VERSION "K24_6MT"

NS_ :

BS_:

BU_: METER PCM UNKNOWN

BO_ 422 SCM_0x1A6: 8 METER
 SG_ HEADLIGHT_STATE : 0|2@1+ (1,0) [0|3] ""  PCM
 SG_ LIGHTING_STATUS_TBD : 2|1@1+ (1,0) [0|1] ""  PCM
 SG_ STATUS_BIT_1 : 3|1@1+ (1,0) [0|1] ""  PCM
 SG_ PARKBRAKE_CURRENT_RAW : 4|1@1+ (1,0) [0|1] ""  PCM
 SG_ CRUISE_CONTROL_SYSTEM_SWITCH_STATUS : 5|3@1+ (1,0) [0|7] ""  PCM
 SG_ UNKNOWN_1 : 8|4@1+ (1,0) [0|15] ""  PCM
 SG_ UNKNOWN_2 : 12|2@1+ (1,0) [0|3] ""  PCM
 SG_ UNKNOWN_3 : 14|2@1+ (1,0) [0|3] ""  PCM
 SG_ UNKNOWN_4 : 16|4@1+ (1,0) [0|15] ""  PCM
 SG_ AC_COMPRESSOR_ON : 20|1@1+ (1,0) [0|1] ""  PCM
 SG_ STATUS_BIT_2 : 21|1@1+ (1,0) [0|1] ""  PCM
 SG_ STATUS_BIT_3 : 22|1@1+ (1,0) [0|1] ""  PCM
 SG_ STATUS_BIT_4 : 23|1@1+ (1,0) [0|1] ""  PCM
 SG_ FUEL_LEVEL_SCALED : 24|8@1+ (1,0) [0|255] ""  PCM
 SG_ FUEL_LEVEL_SENSOR_VOLTAGE : 32|8@1+ (0.01953130029153824,0) [0|4.980481574342251] "V"  PCM
 SG_ STATUS_BIT_5 : 40|1@1+ (1,0) [0|1] ""  PCM
 SG_ STATUS_BIT_6 : 41|1@1+ (1,0) [0|1] ""  PCM
 SG_ CRUISE_SETTING_STATE_TBD : 42|3@1+ (1,0) [0|7] ""  PCM
 SG_ UNKNOWN_5 : 45|2@1+ (1,0) [0|3] ""  PCM
 SG_ CRUISE_MAIN_SWITCH_HIDS_IHCC_ACC_INDICATOR : 47|1@1+ (1,0) [0|1] ""  PCM
 SG_ UNKNOWN_6 : 48|8@1+ (1,0) [0|255] ""  PCM
 SG_ CHECKSUM : 56|4@1+ (1,0) [0|15] ""  PCM
 SG_ COUNTER : 60|2@1+ (1,0) [0|3] ""  PCM
 SG_ STATUS_BIT_7 : 62|1@1+ (1,0) [0|1] ""  PCM
 SG_ STATUS_BIT_8 : 63|1@1+ (1,0) [0|1] ""  PCM
VAL_ 422 CRUISE_CONTROL_SYSTEM_SWITCH_STATUS 0 "DEFAULT" 1 "MAIN_SWITCH" 2 "CANCEL_SWITCH" 3 "SET_SWITCH" 4 "RESUME_SWITCH" 5 "UNKNOWN" 6 "SIGNAL_LOST" 7 "SIGNAL_SHORT" ;

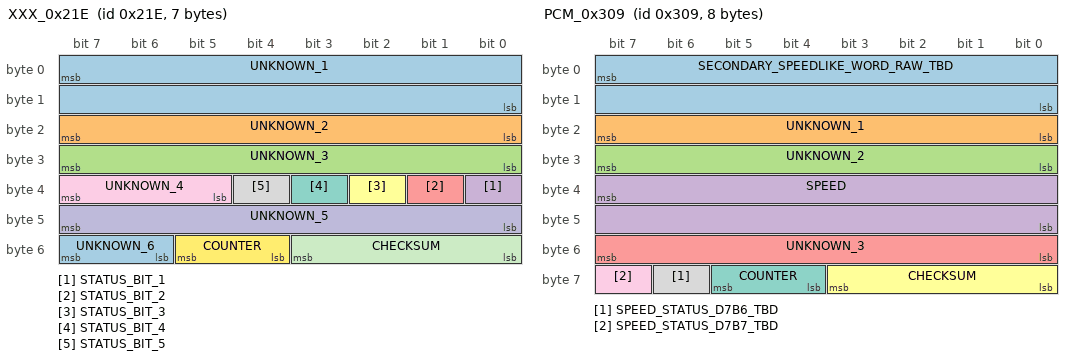
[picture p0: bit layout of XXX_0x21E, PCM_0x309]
BO_ 542 XXX_0x21E: 7 METER
 SG_ UNKNOWN_1 : 7|16@0+ (1,0) [0|65535] ""  PCM
 SG_ UNKNOWN_2 : 16|8@1+ (1,0) [0|255] ""  PCM
 SG_ UNKNOWN_3 : 24|8@1+ (10,-400) [-400|2150] "internal count"  PCM
 SG_ STATUS_BIT_1 : 32|1@1+ (1,0) [0|1] ""  PCM
 SG_ STATUS_BIT_2 : 33|1@1+ (1,0) [0|1] ""  PCM
 SG_ STATUS_BIT_3 : 34|1@1+ (1,0) [0|1] ""  PCM
 SG_ STATUS_BIT_4 : 35|1@1+ (1,0) [0|1] ""  PCM
 SG_ STATUS_BIT_5 : 36|1@1+ (1,0) [0|1] ""  PCM
 SG_ UNKNOWN_4 : 37|3@1+ (1,0) [0|7] ""  PCM
 SG_ UNKNOWN_5 : 40|8@1+ (1,0) [0|255] ""  PCM
 SG_ CHECKSUM : 48|4@1+ (1,0) [0|15] ""  PCM
 SG_ COUNTER : 52|2@1+ (1,0) [0|3] ""  PCM
 SG_ UNKNOWN_6 : 54|2@1+ (1,0) [0|3] ""  PCM

BO_ 660 MICU_0x294: 8 METER
 SG_ UNKNOWN_1 : 0|3@1+ (1,0) [0|7] ""  PCM
 SG_ WIPER_STATUS : 3|2@1+ (1,0) [0|3] ""  PCM
 SG_ BLINKER_LEFT : 5|1@1+ (1,0) [0|1] ""  PCM
 SG_ BLINKER_RIGHT : 6|1@1+ (1,0) [0|1] ""  PCM
 SG_ STATUS_BIT_1 : 7|1@1+ (1,0) [0|1] ""  PCM
 SG_ UNKNOWN_2 : 8|8@1+ (1,0) [0|255] ""  PCM
 SG_ STATUS_BIT_2 : 16|1@1+ (1,0) [0|1] ""  PCM
 SG_ STATUS_BIT_3 : 17|1@1+ (1,0) [0|1] ""  PCM
 SG_ UNKNOWN_3 : 18|2@1+ (1,0) [0|3] ""  PCM
 SG_ STATUS_BIT_4 : 20|1@1+ (1,0) [0|1] ""  PCM
 SG_ STATUS_BIT_5 : 21|1@1+ (1,0) [0|1] ""  PCM
 SG_ CONFIGURED_STATUS_GATE_TBD : 22|1@1+ (1,0) [0|1] ""  PCM
 SG_ STATUS_BIT_6 : 23|1@1+ (1,0) [0|1] ""  PCM
 SG_ TOTAL_MILEAGE : 31|24@0+ (1,0) [0|16777215] "raw"  PCM
 SG_ TRANSITION_LATCH_INPUT_TBD : 48|1@1+ (1,0) [0|1] ""  PCM
 SG_ UNKNOWN_4 : 49|7@1+ (1,0) [0|127] ""  PCM
 SG_ CHECKSUM : 56|4@1+ (1,0) [0|15] ""  PCM
 SG_ COUNTER : 60|2@1+ (1,0) [0|3] ""  PCM
 SG_ PROTOCOL_FLAGS : 62|2@1+ (1,0) [0|3] ""  PCM

BO_ 777 PCM_0x309: 8 METER
 SG_ SECONDARY_SPEEDLIKE_WORD_RAW_TBD : 7|16@0+ (1,0) [0|0] ""  PCM
 SG_ UNKNOWN_1 : 16|8@1+ (1,0) [0|255] ""  PCM
 SG_ UNKNOWN_2 : 24|8@1+ (1,0) [0|255] ""  PCM
 SG_ SPEED : 39|16@0+ (0.01,0) [0|655.35] "km/h"  PCM
 SG_ UNKNOWN_3 : 48|8@1+ (1,0) [0|255] ""  PCM
 SG_ CHECKSUM : 56|4@1+ (1,0) [0|15] ""  PCM
 SG_ COUNTER : 60|2@1+ (1,0) [0|3] ""  PCM
 SG_ SPEED_STATUS_D7B6_TBD : 62|1@1+ (1,0) [0|0] ""  PCM
 SG_ SPEED_STATUS_D7B7_TBD : 63|1@1+ (1,0) [0|0] ""  PCM

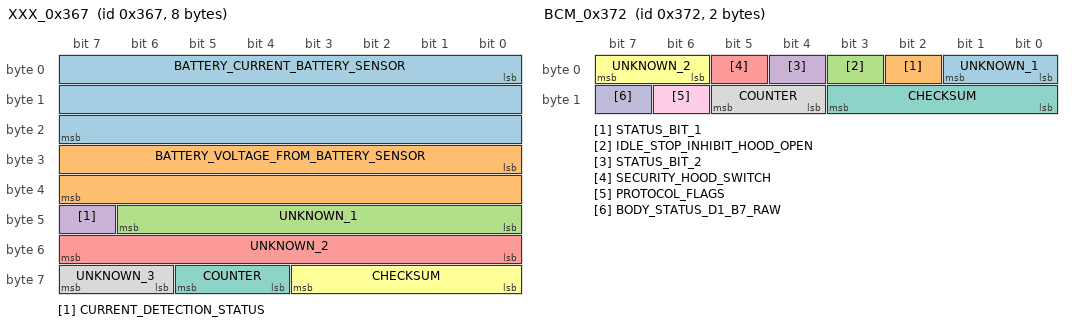
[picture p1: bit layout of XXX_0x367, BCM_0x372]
BO_ 871 XXX_0x367: 8 METER
 SG_ BATTERY_CURRENT_BATTERY_SENSOR : 0|24@1+ (1,0) [0|16777215] "raw"  PCM
 SG_ BATTERY_VOLTAGE_FROM_BATTERY_SENSOR : 24|16@1+ (0.001,0) [0|65.535] "V"  PCM
 SG_ UNKNOWN_1 : 40|7@1+ (1,0) [0|127] ""  PCM
 SG_ CURRENT_DETECTION_STATUS : 47|1@1+ (1,0) [0|1] ""  PCM
 SG_ UNKNOWN_2 : 48|8@1+ (1,0) [0|255] ""  PCM
 SG_ CHECKSUM : 56|4@1+ (1,0) [0|15] ""  PCM
 SG_ COUNTER : 60|2@1+ (1,0) [0|3] ""  PCM
 SG_ UNKNOWN_3 : 62|2@1+ (1,0) [0|3] ""  PCM
VAL_ 871 CURRENT_DETECTION_STATUS 0 "NORMAL_CONDITION" 1 "CIRCUIT_OPEN_FAILURE" ;

BO_ 882 BCM_0x372: 2 METER
 SG_ UNKNOWN_1 : 0|2@1+ (1,0) [0|3] ""  PCM
 SG_ STATUS_BIT_1 : 2|1@1+ (1,0) [0|1] ""  PCM
 SG_ IDLE_STOP_INHIBIT_HOOD_OPEN : 3|1@1+ (1,0) [0|1] ""  PCM
 SG_ STATUS_BIT_2 : 4|1@1+ (1,0) [0|1] ""  PCM
 SG_ SECURITY_HOOD_SWITCH : 5|1@1+ (1,0) [0|1] ""  PCM
 SG_ UNKNOWN_2 : 6|2@1+ (1,0) [0|3] ""  PCM
 SG_ CHECKSUM : 8|4@1+ (1,0) [0|15] ""  PCM
 SG_ COUNTER : 12|2@1+ (1,0) [0|3] ""  PCM
 SG_ PROTOCOL_FLAGS : 14|1@1+ (1,0) [0|0] ""  PCM
 SG_ BODY_STATUS_D1_B7_RAW : 15|1@1+ (1,0) [0|0] ""  PCM
VAL_ 882 IDLE_STOP_INHIBIT_HOOD_OPEN 0 "NORMAL" 1 "INHIBITED" ;

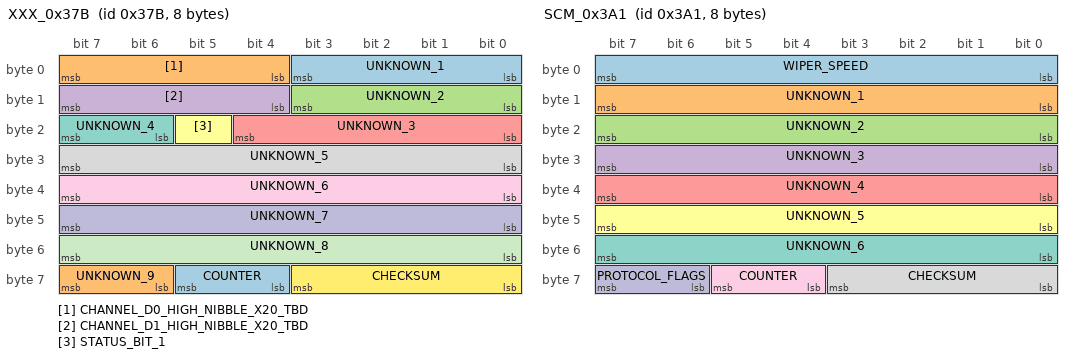
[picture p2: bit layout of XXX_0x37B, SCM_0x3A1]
BO_ 891 XXX_0x37B: 8 METER
 SG_ UNKNOWN_1 : 0|4@1+ (1,0) [0|15] ""  PCM
 SG_ CHANNEL_D0_HIGH_NIBBLE_X20_TBD : 4|4@1+ (1,0) [0|15] ""  PCM
 SG_ UNKNOWN_2 : 8|4@1+ (1,0) [0|15] ""  PCM
 SG_ CHANNEL_D1_HIGH_NIBBLE_X20_TBD : 12|4@1+ (1,0) [0|15] ""  PCM
 SG_ UNKNOWN_3 : 16|5@1+ (1,0) [0|31] ""  PCM
 SG_ STATUS_BIT_1 : 21|1@1+ (1,0) [0|1] ""  PCM
 SG_ UNKNOWN_4 : 22|2@1+ (1,0) [0|3] ""  PCM
 SG_ UNKNOWN_5 : 24|8@1+ (1,0) [0|255] ""  PCM
 SG_ UNKNOWN_6 : 32|8@1+ (1,0) [0|255] ""  PCM
 SG_ UNKNOWN_7 : 40|8@1+ (1,0) [0|255] ""  PCM
 SG_ UNKNOWN_8 : 48|8@1+ (1,0) [0|255] ""  PCM
 SG_ CHECKSUM : 56|4@1+ (1,0) [0|15] ""  PCM
 SG_ COUNTER : 60|2@1+ (1,0) [0|3] ""  PCM
 SG_ UNKNOWN_9 : 62|2@1+ (1,0) [0|3] ""  PCM

BO_ 929 SCM_0x3A1: 8 METER
 SG_ WIPER_SPEED : 0|8@1+ (1,0) [0|255] ""  UNKNOWN
 SG_ UNKNOWN_1 : 8|8@1+ (1,0) [0|255] ""  UNKNOWN
 SG_ UNKNOWN_2 : 16|8@1+ (1,0) [0|255] ""  UNKNOWN
 SG_ UNKNOWN_3 : 24|8@1+ (1,0) [0|255] ""  UNKNOWN
 SG_ UNKNOWN_4 : 32|8@1+ (1,0) [0|255] ""  UNKNOWN
 SG_ UNKNOWN_5 : 40|8@1+ (1,0) [0|255] ""  UNKNOWN
 SG_ UNKNOWN_6 : 48|8@1+ (1,0) [0|255] ""  UNKNOWN
 SG_ CHECKSUM : 56|4@1+ (1,0) [0|15] ""  UNKNOWN
 SG_ COUNTER : 60|2@1+ (1,0) [0|3] ""  UNKNOWN
 SG_ PROTOCOL_FLAGS : 62|2@1+ (1,0) [0|3] ""  UNKNOWN

BO_ 1029 SCM_0x405: 8 METER
 SG_ MIL_DERIVED_STATUS : 0|1@1+ (1,0) [0|0] ""  UNKNOWN
 SG_ UNKNOWN_1 : 1|7@1+ (1,0) [0|0] ""  UNKNOWN
 SG_ UNKNOWN_2 : 8|6@1+ (1,0) [0|0] ""  UNKNOWN
 SG_ REFERENCE_RX333_D0B3_NONZERO : 14|1@1+ (1,0) [0|0] ""  UNKNOWN
 SG_ REFERENCE_RX333_D0B2_NONZERO : 15|1@1+ (1,0) [0|0] ""  UNKNOWN
 SG_ REFERENCE_RX333_D0B5_NONZERO : 16|1@1+ (1,0) [0|0] ""  UNKNOWN
 SG_ REFERENCE_RX333_D0B4_NONZERO : 17|1@1+ (1,0) [0|0] ""  UNKNOWN
 SG_ STATUS_BIT_1 : 18|1@1+ (1,0) [0|0] ""  UNKNOWN
 SG_ SHARED_431DC_STATUS_D2B3_TBD : 19|1@1+ (1,0) [0|0] ""  UNKNOWN
 SG_ UNKNOWN_3 : 20|4@1+ (1,0) [0|0] ""  UNKNOWN
 SG_ UNKNOWN_4 : 24|8@1+ (1,0) [0|255] ""  UNKNOWN
 SG_ UNKNOWN_5 : 32|5@1+ (1,0) [0|31] ""  UNKNOWN
 SG_ DOOR_OPEN_FL : 37|1@1+ (1,0) [0|1] ""  UNKNOWN
 SG_ DOOR_OPEN_FR : 38|1@1+ (1,0) [0|1] ""  UNKNOWN
 SG_ DOOR_OPEN_RL : 39|1@1+ (1,0) [0|1] ""  UNKNOWN
 SG_ DOOR_OPEN_RR : 40|1@1+ (1,0) [0|1] ""  UNKNOWN
 SG_ TRUNK_OPEN : 41|1@1+ (1,0) [0|1] ""  UNKNOWN
 SG_ IMMOBILIZER_LAMP_STATE_TBD : 42|1@1+ (1,0) [0|0] ""  UNKNOWN
 SG_ UNKNOWN_6 : 43|5@1+ (1,0) [0|0] ""  UNKNOWN
 SG_ UNKNOWN_7 : 48|8@1+ (1,0) [0|255] ""  UNKNOWN
 SG_ CHECKSUM : 56|4@1+ (1,0) [0|15] ""  UNKNOWN
 SG_ COUNTER : 60|2@1+ (1,0) [0|3] ""  UNKNOWN
 SG_ PROTOCOL_FLAGS : 62|2@1+ (1,0) [0|3] ""  UNKNOWN

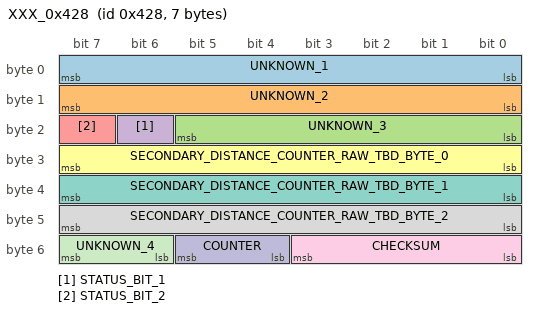
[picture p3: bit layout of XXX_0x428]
BO_ 1064 XXX_0x428: 7 METER
 SG_ UNKNOWN_1 : 0|8@1+ (1,0) [0|255] ""  PCM
 SG_ UNKNOWN_2 : 8|8@1+ (1,0) [0|255] ""  PCM
 SG_ UNKNOWN_3 : 16|6@1+ (1,0) [0|63] ""  PCM
 SG_ STATUS_BIT_1 : 22|1@1+ (1,0) [0|1] ""  PCM
 SG_ STATUS_BIT_2 : 23|1@1+ (1,0) [0|1] ""  PCM
 SG_ SECONDARY_DISTANCE_COUNTER_RAW_TBD_BYTE_0 : 24|8@1+ (1,0) [0|255] ""  PCM
 SG_ SECONDARY_DISTANCE_COUNTER_RAW_TBD_BYTE_1 : 32|8@1+ (1,0) [0|255] ""  PCM
 SG_ SECONDARY_DISTANCE_COUNTER_RAW_TBD_BYTE_2 : 40|8@1+ (1,0) [0|255] ""  PCM
 SG_ CHECKSUM : 48|4@1+ (1,0) [0|15] ""  PCM
 SG_ COUNTER : 52|2@1+ (1,0) [0|3] ""  PCM
 SG_ UNKNOWN_4 : 54|2@1+ (1,0) [0|3] ""  PCM

BO_ 1088 XXX_0x440: 8 METER
 SG_ MUX M : 0|8@1+ (1,0) [0|255] ""  PCM
 SG_ UNKNOWN_1 m49 : 8|8@1+ (1,0) [0|255] ""  PCM
 SG_ P32_ESTIMATED_BATTERY_RESISTANCE_BATTERY_SENSOR m50 : 8|16@1+ (1,0) [0|65535] "raw"  PCM
 SG_ UNKNOWN_2 m51 : 8|8@1+ (1,0) [0|255] ""  PCM
 SG_ UNKNOWN_3 m57 : 8|8@1+ (1,0) [0|255] ""  PCM
 SG_ UNKNOWN_4 m58 : 8|8@1+ (1,-40) [-40|215] "degC"  PCM
 SG_ UNKNOWN_5 m0 : 8|8@1+ (1,0) [0|255] ""  PCM
 SG_ UNKNOWN_6 m49 : 16|8@1+ (1,0) [0|255] ""  PCM
 SG_ UNKNOWN_7 m51 : 16|8@1+ (1,0) [0|255] ""  PCM
 SG_ UNKNOWN_8 m57 : 16|8@1+ (1,0) [0|255] ""  PCM
 SG_ UNKNOWN_9 m58 : 16|8@1+ (1,0) [0|255] ""  PCM
 SG_ UNKNOWN_10 m0 : 16|8@1+ (1,0) [0|255] ""  PCM
 SG_ P31_ESTIMATED_BATTERY_TEMPERATURE m49 : 24|8@1+ (1,-40) [-40|215] "degC"  PCM
 SG_ UNKNOWN_11 m50 : 24|16@1+ (3.5172,0) [0|230499.702] "A*s"  PCM
 SG_ UNKNOWN_12 m51 : 24|8@1+ (1,0) [0|255] ""  PCM
 SG_ P39_ESTIMATED_BATTERY_QUIESCENT_OR_OPEN_CIRCUIT_VOLTAGE m57 : 24|8@1+ (4,4600) [4600|5620] "code"  PCM
 SG_ UNKNOWN_13 m58 : 24|16@1+ (1,0) [0|65535] ""  PCM
 SG_ UNKNOWN_14 m0 : 24|8@1+ (1,0) [0|255] ""  PCM
 SG_ P31_SURVEY_INFOMATION_BATTERY_MANAGEMENT_1 m49 : 32|8@1+ (1,0) [0|255] "raw"  PCM
 SG_ UNKNOWN_15 m51 : 32|8@1+ (1,0) [0|255] ""  PCM
 SG_ P39_ESTIMATED_BATTERY_ABILITY_TO_DELIVER_CURRENT_VOLTAGE_SOH m57 : 32|8@1+ (1,0) [0|255] "raw"  PCM
 SG_ UNKNOWN_16 m0 : 32|8@1+ (1,0) [0|255] ""  PCM
 SG_ UNKNOWN_17 m49 : 40|3@1+ (1,0) [0|7] ""  PCM
 SG_ UNKNOWN_18 m50 : 40|16@1+ (3.5172,0) [0|230499.702] "A*s"  PCM
 SG_ UNKNOWN_19 m51 : 40|8@1+ (1,0) [0|255] ""  PCM
 SG_ P39_ESTIMATED_BATTERY_VOLTAGE_AT_THE_SPECIFIED_HIGH_LOAD m57 : 40|8@1+ (25,0) [0|6375] "code"  PCM
 SG_ UNKNOWN_20 m58 : 40|16@1+ (1,0) [0|65535] ""  PCM
 SG_ UNKNOWN_21 m0 : 40|8@1+ (1,0) [0|255] ""  PCM
 SG_ UNKNOWN_22 m49 : 43|2@1+ (1,0) [0|3] ""  PCM
 SG_ STATUS_BIT_1 m49 : 45|1@1+ (1,0) [0|1] ""  PCM
 SG_ STATUS_BIT_2 m49 : 46|1@1+ (1,0) [0|1] ""  PCM
 SG_ STATUS_BIT_3 m49 : 47|1@1+ (1,0) [0|1] ""  PCM
 SG_ UNKNOWN_23 m49 : 48|3@1+ (1,0) [0|7] ""  PCM
 SG_ UNKNOWN_24 m51 : 48|8@1+ (1,0) [0|255] ""  PCM
 SG_ P39_RESET_ON_BATTERY_SENSOR m57 : 48|1@1+ (1,0) [0|1] ""  PCM
 SG_ UNKNOWN_25 m0 : 48|8@1+ (1,0) [0|255] ""  PCM
 SG_ P39_SURVEY_INFOMATION_BATTERY_MANAGEMENT_3 m57 : 49|1@1+ (1,0) [0|1] ""  PCM
 SG_ STATUS_BIT_4 m57 : 50|1@1+ (1,0) [0|1] ""  PCM
 SG_ UNKNOWN_26 m49 : 51|3@1+ (1,0) [0|7] ""  PCM
 SG_ STATUS_BIT_5 m57 : 51|1@1+ (1,0) [0|1] ""  PCM
 SG_ UNKNOWN_27 m57 : 52|3@1+ (1,0) [0|7] ""  PCM
 SG_ STATUS_BIT_6 m49 : 54|1@1+ (1,0) [0|1] ""  PCM
 SG_ STATUS_BIT_7 m49 : 55|1@1+ (1,0) [0|1] ""  PCM
 SG_ STATUS_BIT_8 m57 : 55|1@1+ (1,0) [0|1] ""  PCM
 SG_ CHECKSUM : 56|4@1+ (1,0) [0|15] ""  PCM
 SG_ COUNTER : 60|2@1+ (1,0) [0|3] ""  PCM
 SG_ PAGE_STATE : 62|2@1+ (1,0) [0|3] ""  PCM
SG_MUL_VAL_ 1088 UNKNOWN_1 MUX 49-49;
SG_MUL_VAL_ 1088 P32_ESTIMATED_BATTERY_RESISTANCE_BATTERY_SENSOR MUX 50-50;
SG_MUL_VAL_ 1088 UNKNOWN_2 MUX 51-51;
SG_MUL_VAL_ 1088 UNKNOWN_3 MUX 57-57;
SG_MUL_VAL_ 1088 UNKNOWN_4 MUX 58-58;
SG_MUL_VAL_ 1088 UNKNOWN_5 MUX 0-48, 52-56, 59-255;
SG_MUL_VAL_ 1088 UNKNOWN_6 MUX 49-49;
SG_MUL_VAL_ 1088 UNKNOWN_7 MUX 51-51;
SG_MUL_VAL_ 1088 UNKNOWN_8 MUX 57-57;
SG_MUL_VAL_ 1088 UNKNOWN_9 MUX 58-58;
SG_MUL_VAL_ 1088 UNKNOWN_10 MUX 0-48, 52-56, 59-255;
SG_MUL_VAL_ 1088 P31_ESTIMATED_BATTERY_TEMPERATURE MUX 49-49;
SG_MUL_VAL_ 1088 UNKNOWN_11 MUX 50-50;
SG_MUL_VAL_ 1088 UNKNOWN_12 MUX 51-51;
SG_MUL_VAL_ 1088 P39_ESTIMATED_BATTERY_QUIESCENT_OR_OPEN_CIRCUIT_VOLTAGE MUX 57-57;
SG_MUL_VAL_ 1088 UNKNOWN_13 MUX 58-58;
SG_MUL_VAL_ 1088 UNKNOWN_14 MUX 0-48, 52-56, 59-255;
SG_MUL_VAL_ 1088 P31_SURVEY_INFOMATION_BATTERY_MANAGEMENT_1 MUX 49-49;
SG_MUL_VAL_ 1088 UNKNOWN_15 MUX 51-51;
SG_MUL_VAL_ 1088 P39_ESTIMATED_BATTERY_ABILITY_TO_DELIVER_CURRENT_VOLTAGE_SOH MUX 57-57;
SG_MUL_VAL_ 1088 UNKNOWN_16 MUX 0-48, 52-56, 59-255;
SG_MUL_VAL_ 1088 UNKNOWN_17 MUX 49-49;
SG_MUL_VAL_ 1088 UNKNOWN_18 MUX 50-50;
SG_MUL_VAL_ 1088 UNKNOWN_19 MUX 51-51;
SG_MUL_VAL_ 1088 P39_ESTIMATED_BATTERY_VOLTAGE_AT_THE_SPECIFIED_HIGH_LOAD MUX 57-57;
SG_MUL_VAL_ 1088 UNKNOWN_20 MUX 58-58;
SG_MUL_VAL_ 1088 UNKNOWN_21 MUX 0-48, 52-56, 59-255;
SG_MUL_VAL_ 1088 UNKNOWN_22 MUX 49-49;
SG_MUL_VAL_ 1088 STATUS_BIT_1 MUX 49-49;
SG_MUL_VAL_ 1088 STATUS_BIT_2 MUX 49-49;
SG_MUL_VAL_ 1088 STATUS_BIT_3 MUX 49-49;
SG_MUL_VAL_ 1088 UNKNOWN_23 MUX 49-49;
SG_MUL_VAL_ 1088 UNKNOWN_24 MUX 51-51;
SG_MUL_VAL_ 1088 P39_RESET_ON_BATTERY_SENSOR MUX 57-57;
SG_MUL_VAL_ 1088 UNKNOWN_25 MUX 0-48, 52-56, 59-255;
SG_MUL_VAL_ 1088 P39_SURVEY_INFOMATION_BATTERY_MANAGEMENT_3 MUX 57-57;
SG_MUL_VAL_ 1088 STATUS_BIT_4 MUX 57-57;
SG_MUL_VAL_ 1088 UNKNOWN_26 MUX 49-49;
SG_MUL_VAL_ 1088 STATUS_BIT_5 MUX 57-57;
SG_MUL_VAL_ 1088 UNKNOWN_27 MUX 57-57;
SG_MUL_VAL_ 1088 STATUS_BIT_6 MUX 49-49;
SG_MUL_VAL_ 1088 STATUS_BIT_7 MUX 49-49;
SG_MUL_VAL_ 1088 STATUS_BIT_8 MUX 57-57;
